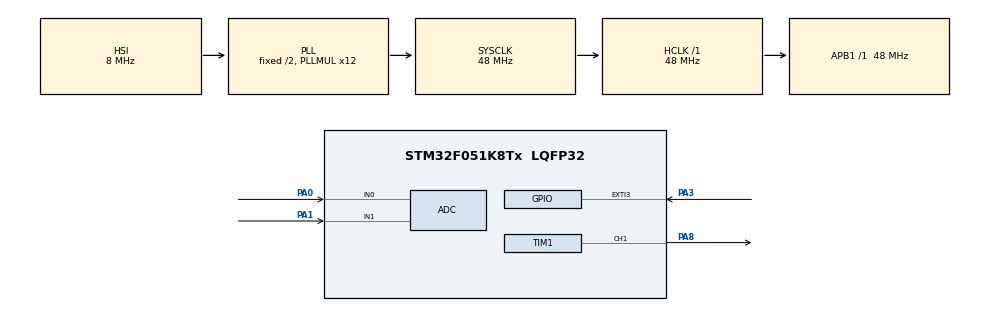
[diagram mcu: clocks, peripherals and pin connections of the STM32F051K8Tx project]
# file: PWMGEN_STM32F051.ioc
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ADC.ContinuousConvMode=ENABLE
ADC.DMAContinuousRequests=ENABLE
ADC.Overrun=ADC_OVR_DATA_OVERWRITTEN
Dma.ADC.0.Direction=DMA_PERIPH_TO_MEMORY
Dma.ADC.0.Instance=DMA1_Channel1
Dma.ADC.0.MemDataAlignment=DMA_MDATAALIGN_WORD
Dma.ADC.0.MemInc=DMA_MINC_ENABLE
Dma.ADC.0.Mode=DMA_CIRCULAR
Dma.ADC.0.PeriphDataAlignment=DMA_PDATAALIGN_WORD
Dma.ADC.0.PeriphInc=DMA_PINC_DISABLE
Dma.ADC.0.Priority=DMA_PRIORITY_LOW
Dma.Request0=ADC
Mcu.Family=STM32F0
Mcu.Name=STM32F051K8Tx
Mcu.Package=LQFP32
NVIC.DMA1_Channel1_IRQn=true\:0\:0\:false\:false\:true\:false\:true
NVIC.EXTI2_3_IRQn=true\:0\:0\:false\:false\:true\:true\:true
NVIC.TIM16_IRQn=true\:0\:0\:false\:false\:true\:true\:true
NVIC.TIM17_IRQn=true\:0\:0\:false\:false\:true\:true\:true
NVIC.TIM1_BRK_UP_TRG_COM_IRQn=true\:0\:0\:false\:false\:true\:true\:true
PA0.Mode=IN0
PA0.Signal=ADC_IN0
PA1.Mode=IN1
PA1.Signal=ADC_IN1
PA13.Mode=Serial_Wire
PA13.Signal=SYS_SWDIO
PA14.Mode=Serial_Wire
PA14.Signal=SYS_SWCLK
PA3.GPIO_ModeDefaultEXTI=GPIO_MODE_IT_FALLING
PA3.GPIO_PuPd=GPIO_PULLUP
PA3.Signal=GPXTI3
PA8.Signal=S_TIM1_CH1
ProjectManager.HeapSize=0x200
ProjectManager.StackSize=0x400
ProjectManager.TargetToolchain=TrueSTUDIO
RCC.AHBFreq_Value=48000000
RCC.APB1Freq_Value=48000000
RCC.APB1TimFreq_Value=48000000
RCC.HCLKFreq_Value=48000000
RCC.PLLMUL=RCC_PLL_MUL12
RCC.SYSCLKFreq_VALUE=48000000
RCC.SYSCLKSource=RCC_SYSCLKSOURCE_PLLCLK
SH.S_TIM1_CH1.0=TIM1_CH1,PWM Generation1 CH1
TIM1.AutoReloadPreload=TIM_AUTORELOAD_PRELOAD_ENABLE
TIM1.Channel-PWM\ Generation1\ CH1=TIM_CHANNEL_1
TIM1.Period=65535
TIM1.Prescaler=2
TIM1.TIM_MasterOutputTrigger=TIM_TRGO_UPDATE
TIM16.AutoReloadPreload=TIM_AUTORELOAD_PRELOAD_ENABLE
TIM16.Period=65535
TIM16.Prescaler=65535
TIM17.AutoReloadPreload=TIM_AUTORELOAD_PRELOAD_ENABLE
TIM17.Period=8191
TIM17.Prescaler=16
VP_TIM16_VS_ClockSourceINT.Mode=Enable_Timer
VP_TIM17_VS_ClockSourceINT.Mode=Enable_Timer
VP_TIM1_VS_ClockSourceINT.Mode=Internal
board=custom

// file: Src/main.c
/* USER CODE BEGIN Header */
/**
  ******************************************************************************
  * @file           : main.c
  * @brief          : Main program body
  ******************************************************************************
  * @attention
  *
  * <h2><center>&copy; Copyright (c) 2019 STMicroelectronics.
  * All rights reserved.</center></h2>
  *
  * This software component is licensed by ST under BSD 3-Clause license,
  * the "License"; You may not use this file except in compliance with the
  * License. You may obtain a copy of the License at:
  *                        opensource.org/licenses/BSD-3-Clause
  *
  ******************************************************************************
  */
/* USER CODE END Header */

#include "main.h"
#include "adc.h"
#include "dma.h"
#include "tim.h"
#include "gpio.h"

/* USER CODE BEGIN PV */
uint32_t input[SAMPLE_RESOLUTION] = {0};
uint32_t lastdebouncetime = 0;
uint32_t maxdebouncedelay = 500;
/* USER CODE END PV */

void SystemClock_Config(void);

int main(void)
{

  /* MCU Configuration--------------------------------------------------------*/

  /* Reset of all peripherals, Initializes the Flash interface and the Systick. */
  HAL_Init();

  /* Configure the system clock */
  SystemClock_Config();

  /* Initialize all configured peripherals */
  MX_GPIO_Init();
  MX_DMA_Init();
  MX_TIM1_Init();
  MX_ADC_Init();
  MX_TIM17_Init();
  MX_TIM16_Init();
  /* USER CODE BEGIN 2 */
  HAL_ADCEx_Calibration_Start(&hadc);
  HAL_ADC_Start_DMA(&hadc, input, SAMPLE_RESOLUTION);
  HAL_TIM_PWM_Start(&htim1, TIM_CHANNEL_1);
  HAL_TIM_Base_Start_IT(&htim17);
  HAL_TIM_Base_Start_IT(&htim16);

  /* USER CODE END 2 */

  /* Infinite loop */
  while (1)
  {

  }
}

void SystemClock_Config(void)
{
  RCC_OscInitTypeDef RCC_OscInitStruct = {0};
  RCC_ClkInitTypeDef RCC_ClkInitStruct = {0};

  /** Initializes the CPU, AHB and APB busses clocks
  */
  RCC_OscInitStruct.OscillatorType = RCC_OSCILLATORTYPE_HSI|RCC_OSCILLATORTYPE_HSI14;
  RCC_OscInitStruct.HSIState = RCC_HSI_ON;
  RCC_OscInitStruct.HSI14State = RCC_HSI14_ON;
  RCC_OscInitStruct.HSICalibrationValue = RCC_HSICALIBRATION_DEFAULT;
  RCC_OscInitStruct.HSI14CalibrationValue = 16;
  RCC_OscInitStruct.PLL.PLLState = RCC_PLL_ON;
  RCC_OscInitStruct.PLL.PLLSource = RCC_PLLSOURCE_HSI;
  RCC_OscInitStruct.PLL.PLLMUL = RCC_PLL_MUL12;
  RCC_OscInitStruct.PLL.PREDIV = RCC_PREDIV_DIV1;
  if (HAL_RCC_OscConfig(&RCC_OscInitStruct) != HAL_OK)
  {
    Error_Handler();
  }
  /** Initializes the CPU, AHB and APB busses clocks
  */
  RCC_ClkInitStruct.ClockType = RCC_CLOCKTYPE_HCLK|RCC_CLOCKTYPE_SYSCLK
                              |RCC_CLOCKTYPE_PCLK1;
  RCC_ClkInitStruct.SYSCLKSource = RCC_SYSCLKSOURCE_PLLCLK;
  RCC_ClkInitStruct.AHBCLKDivider = RCC_SYSCLK_DIV1;
  RCC_ClkInitStruct.APB1CLKDivider = RCC_HCLK_DIV1;

  if (HAL_RCC_ClockConfig(&RCC_ClkInitStruct, FLASH_LATENCY_1) != HAL_OK)
  {
    Error_Handler();
  }
}

void Error_Handler(void)
{
}

/************************ (C) COPYRIGHT STMicroelectronics *****END OF FILE****/
